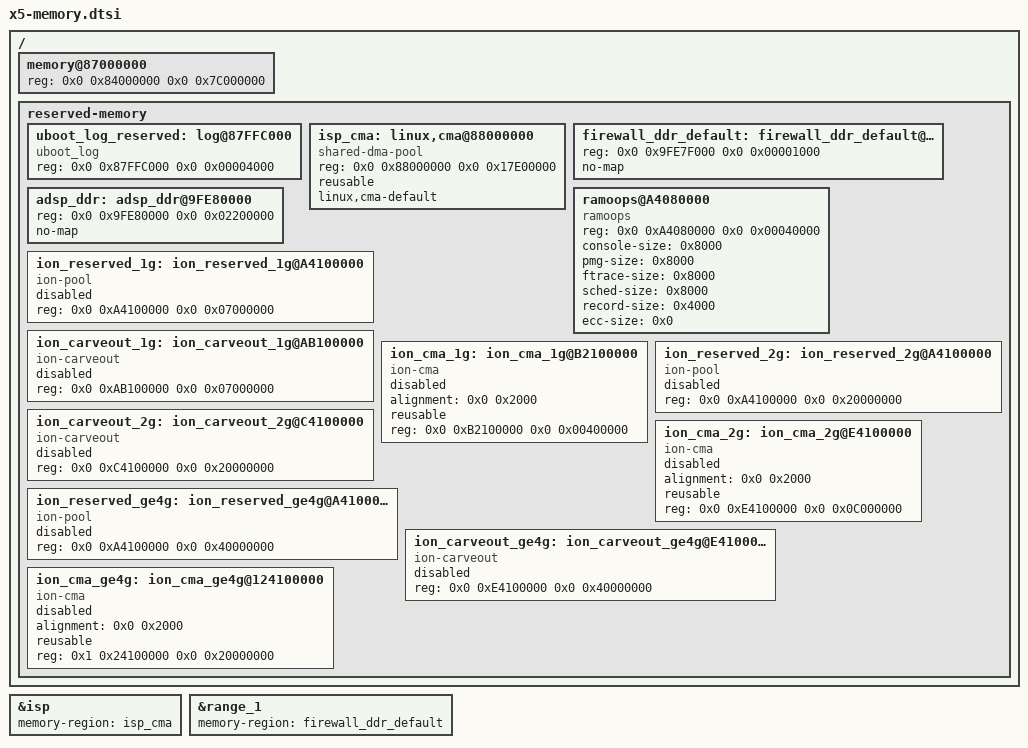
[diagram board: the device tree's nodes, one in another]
// SPDX-License-Identifier: GPL-2.0
/*
 * dtsi for Sunrise5 platform
 *
 * Copyright (C) 2024 D-Robotics Inc.
 *
 */

#include "x5.dtsi"

/ {
	memory@87000000 {
		device_type = "memory";
		reg = <0x0 0x84000000 0x0 0x7C000000>;
		/* Expect Bootloader to properly configure total memory size */
	};

	reserved-memory {
		#address-cells = <2>;
		#size-cells = <2>;
		ranges;

		/* dtb 2M 0x87FDC000---0x87FFC000*/
		/* uboot log 16k 0x87FFC000---0x88000000*/
		uboot_log_reserved: log@87FFC000 {
			compatible = "uboot_log";
			reg = <0x0 0x87FFC000 0x0 0x00004000>;  /* 16K */
			status = "okay";
		};

		isp_cma: linux,cma@88000000 {
			compatible = "shared-dma-pool";
			reg = <0x0 0x88000000 0x0 0x17E00000>; /* 382MB */
			reusable;
			linux,cma-default;
		};

		/* use as firewall default address */
		firewall_ddr_default: firewall_ddr_default@9FE7F000 {
			reg = <0x0 0x9FE7F000 0x0 0x00001000>;
			no-map;
		};

		adsp_ddr: adsp_ddr@9FE80000 {
			reg = <0x0 0x9FE80000 0x0 0x02200000>;
			no-map;
		};

		ramoops@A4080000 {
			compatible = "ramoops";
			reg = <0x0 0xA4080000 0x0 0x00040000>;
			console-size = <0x8000>;
			pmg-size = <0x8000>;
			ftrace-size = <0x8000>;
			sched-size  = <0x8000>;
			record-size = <0x4000>;
			ecc-size = <0x0>;
		};

		/* UBoot will enable corresponding node when ddr size is confirmed */
		ion_reserved_1g: ion_reserved_1g@A4100000 {
			compatible = "ion-pool";
			reg = <0x0 0xA4100000 0x0 0x07000000>; /* 112MiB */
			status = "disabled";
		};

		ion_carveout_1g: ion_carveout_1g@AB100000 {
			compatible = "ion-carveout";
			reg = <0x0 0xAB100000 0x0 0x07000000>; /* 112MiB */
			status = "disabled";
		};

		ion_cma_1g: ion_cma_1g@B2100000 {
			compatible = "ion-cma";
			alignment = <0x0 0x2000>;
			reusable;
			reg = <0x0 0xB2100000 0x0 0x00400000>; /* 64MiB */
			status = "disabled";
		};

		ion_reserved_2g: ion_reserved_2g@A4100000 {
			compatible = "ion-pool";
			reg = <0x0 0xA4100000 0x0 0x20000000>; /* 512MiB */
			status = "disabled";
		};

		ion_carveout_2g: ion_carveout_2g@C4100000 {
			compatible = "ion-carveout";
			reg = <0x0 0xC4100000 0x0 0x20000000>; /* 512MiB */
			status = "disabled";
		};

		ion_cma_2g: ion_cma_2g@E4100000 {
			compatible = "ion-cma";
			alignment = <0x0 0x2000>;
			reusable;
			reg = <0x0 0xE4100000 0x0 0x0C000000>; /* 192MiB */
			status = "disabled";
		};

		ion_reserved_ge4g: ion_reserved_ge4g@A4100000 {
			compatible = "ion-pool";
			reg = <0x0 0xA4100000 0x0 0x40000000>; /* 1GiB */
			status = "disabled";
		};

		ion_carveout_ge4g: ion_carveout_ge4g@E4100000 {
			compatible = "ion-carveout";
			reg = <0x0 0xE4100000 0x0 0x40000000>; /* 1GiB */
			status = "disabled";
		};

		ion_cma_ge4g: ion_cma_ge4g@124100000 {
			compatible = "ion-cma";
			alignment = <0x0 0x2000>;
			reusable;
			reg = <0x1 0x24100000 0x0 0x20000000>; /* 512MiB */
			status = "disabled";
		};
		/* The remaining memory is used as kernel heaps,
		 * please reserve with CAUTION!
		 */
	};
};

&isp {
	memory-region = <&isp_cma>;
};

&range_1 {
        memory-region = <&firewall_ddr_default>;
};
